# regs register map
Registers from a debugger description file.
Registers are 32-bit, access not given, no defined reset value unless marked. A register's access mark holds for its fields unless they carry their own. Addresses are absolute; registers are grouped by the start of their names; lines under a group give offsets from that group; [hi:lo] are bit positions; {n}, {i} and the like mark numbered series; 'fields as' and 'values as' point back to an identical list; <NAME> marks a mode.

## SC1
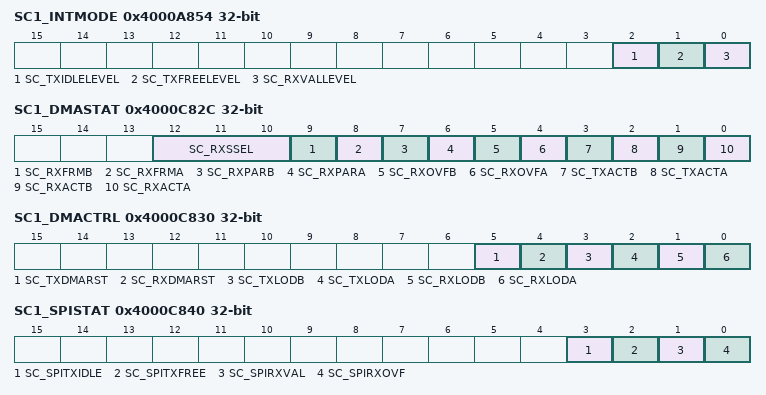
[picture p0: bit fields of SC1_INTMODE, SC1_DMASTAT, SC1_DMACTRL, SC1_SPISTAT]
0x4000A854 SC1_INTMODE
  [2] SC_TXIDLELEVEL, [1] SC_TXFREELEVEL, [0] SC_RXVALLEVEL
0x4000C800 SC1_RXBEGA
0x4000C804 SC1_RXENDA
0x4000C808 SC1_RXBEGB
0x4000C80C SC1_RXENDB
0x4000C810 SC1_TXBEGA
0x4000C814 SC1_TXENDA
0x4000C818 SC1_TXBEGB
0x4000C81C SC1_TXENDB
0x4000C820 SC1_RXCNTA
0x4000C824 SC1_RXCNTB
0x4000C828 SC1_TXCNT
0x4000C82C SC1_DMASTAT
  [12:10] SC_RXSSEL, [9] SC_RXFRMB, [8] SC_RXFRMA, [7] SC_RXPARB, [6] SC_RXPARA, [5] SC_RXOVFB, [4] SC_RXOVFA, [3] SC_TXACTB, [2] SC_TXACTA, [1] SC_RXACTB, [0] SC_RXACTA
0x4000C830 SC1_DMACTRL
  [5] SC_TXDMARST, [4] SC_RXDMARST, [3] SC_TXLODB, [2] SC_TXLODA, [1] SC_RXLODB, [0] SC_RXLODA
0x4000C834 SC1_RXERRA
0x4000C838 SC1_RXERRB
0x4000C83C SC1_DATA
0x4000C840 SC1_SPISTAT
  [3] SC_SPITXIDLE, [2] SC_SPITXFREE, [1] SC_SPIRXVAL, [0] SC_SPIRXOVF
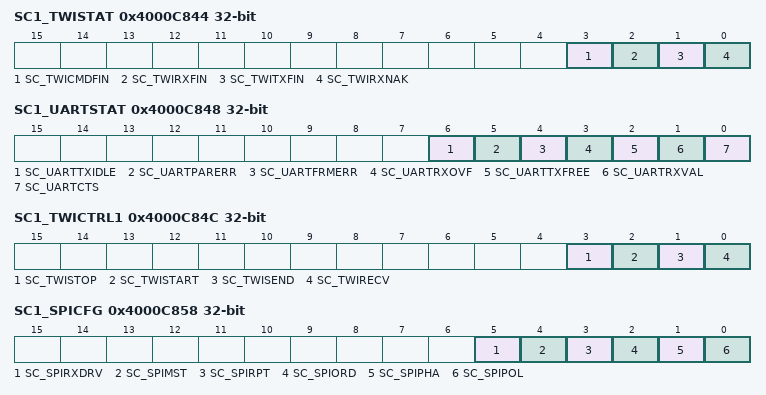
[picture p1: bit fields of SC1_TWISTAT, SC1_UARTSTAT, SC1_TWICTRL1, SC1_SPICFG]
0x4000C844 SC1_TWISTAT
  [3] SC_TWICMDFIN, [2] SC_TWIRXFIN, [1] SC_TWITXFIN, [0] SC_TWIRXNAK
0x4000C848 SC1_UARTSTAT
  [6] SC_UARTTXIDLE, [5] SC_UARTPARERR, [4] SC_UARTFRMERR, [3] SC_UARTRXOVF, [2] SC_UARTTXFREE, [1] SC_UARTRXVAL, [0] SC_UARTCTS
0x4000C84C SC1_TWICTRL1
  [3] SC_TWISTOP, [2] SC_TWISTART, [1] SC_TWISEND, [0] SC_TWIRECV
0x4000C850 SC1_TWICTRL2
0x4000C854 SC1_MODE
0x4000C858 SC1_SPICFG
  [5] SC_SPIRXDRV, [4] SC_SPIMST, [3] SC_SPIRPT, [2] SC_SPIORD, [1] SC_SPIPHA, [0] SC_SPIPOL
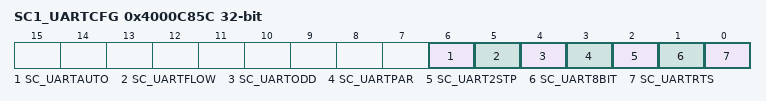
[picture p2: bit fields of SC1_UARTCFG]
0x4000C85C SC1_UARTCFG
  [6] SC_UARTAUTO, [5] SC_UARTFLOW, [4] SC_UARTODD, [3] SC_UARTPAR, [2] SC_UART2STP, [1] SC_UART8BIT, [0] SC_UARTRTS
0x4000C860 SC1_RATELIN
0x4000C864 SC1_RATEEXP
0x4000C868 SC1_UARTPER
0x4000C86C SC1_UARTFRAC
0x4000C870 SC1_RXCNTSAVED

## SC2
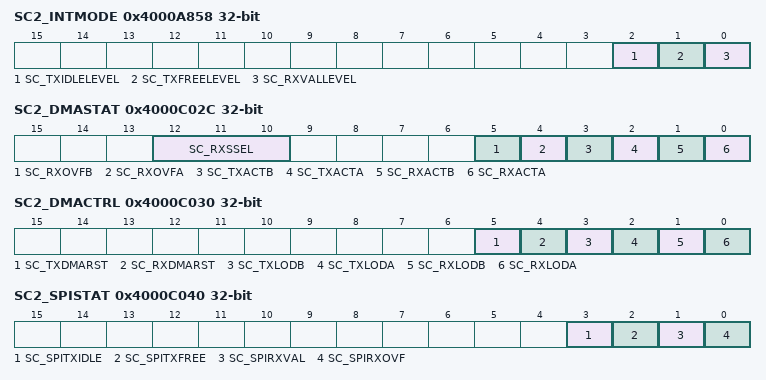
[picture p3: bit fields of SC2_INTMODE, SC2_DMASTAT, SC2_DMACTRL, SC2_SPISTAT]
0x4000A858 SC2_INTMODE
  [2] SC_TXIDLELEVEL, [1] SC_TXFREELEVEL, [0] SC_RXVALLEVEL
0x4000C000 SC2_RXBEGA
0x4000C004 SC2_RXENDA
0x4000C008 SC2_RXBEGB
0x4000C00C SC2_RXENDB
0x4000C010 SC2_TXBEGA
0x4000C014 SC2_TXENDA
0x4000C018 SC2_TXBEGB
0x4000C01C SC2_TXENDB
0x4000C020 SC2_RXCNTA
0x4000C024 SC2_RXCNTB
0x4000C028 SC2_TXCNT
0x4000C02C SC2_DMASTAT
  [12:10] SC_RXSSEL, [5] SC_RXOVFB, [4] SC_RXOVFA, [3] SC_TXACTB, [2] SC_TXACTA, [1] SC_RXACTB, [0] SC_RXACTA
0x4000C030 SC2_DMACTRL
  [5] SC_TXDMARST, [4] SC_RXDMARST, [3] SC_TXLODB, [2] SC_TXLODA, [1] SC_RXLODB, [0] SC_RXLODA
0x4000C034 SC2_RXERRA
0x4000C038 SC2_RXERRB
0x4000C03C SC2_DATA
0x4000C040 SC2_SPISTAT
  [3] SC_SPITXIDLE, [2] SC_SPITXFREE, [1] SC_SPIRXVAL, [0] SC_SPIRXOVF
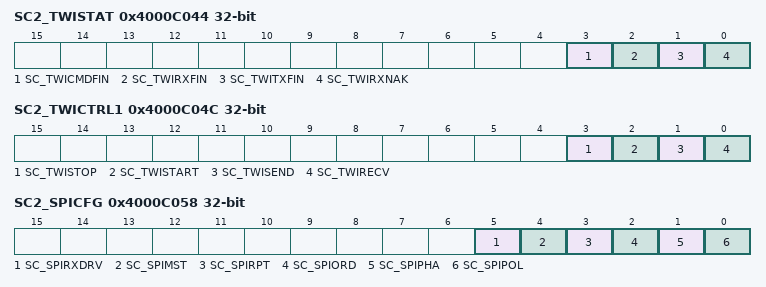
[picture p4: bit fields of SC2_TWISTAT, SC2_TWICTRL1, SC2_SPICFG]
0x4000C044 SC2_TWISTAT
  [3] SC_TWICMDFIN, [2] SC_TWIRXFIN, [1] SC_TWITXFIN, [0] SC_TWIRXNAK
0x4000C04C SC2_TWICTRL1
  [3] SC_TWISTOP, [2] SC_TWISTART, [1] SC_TWISEND, [0] SC_TWIRECV
0x4000C050 SC2_TWICTRL2
0x4000C054 SC2_MODE
0x4000C058 SC2_SPICFG
  [5] SC_SPIRXDRV, [4] SC_SPIMST, [3] SC_SPIRPT, [2] SC_SPIORD, [1] SC_SPIPHA, [0] SC_SPIPOL
0x4000C060 SC2_RATELIN
0x4000C064 SC2_RATEEXP
0x4000C070 SC2_RXCNTSAVED

## GPIO
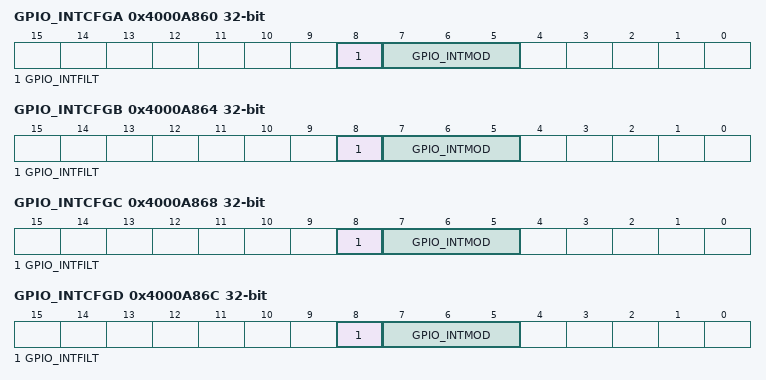
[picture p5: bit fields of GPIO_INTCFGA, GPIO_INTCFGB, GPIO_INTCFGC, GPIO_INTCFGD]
0x4000A860 GPIO_INTCFGA
  [8] GPIO_INTFILT, [7:5] GPIO_INTMOD
0x4000A864 GPIO_INTCFGB
  [8] GPIO_INTFILT, [7:5] GPIO_INTMOD
0x4000A868 GPIO_INTCFGC
  [8] GPIO_INTFILT, [7:5] GPIO_INTMOD
0x4000A86C GPIO_INTCFGD
  [8] GPIO_INTFILT, [7:5] GPIO_INTMOD
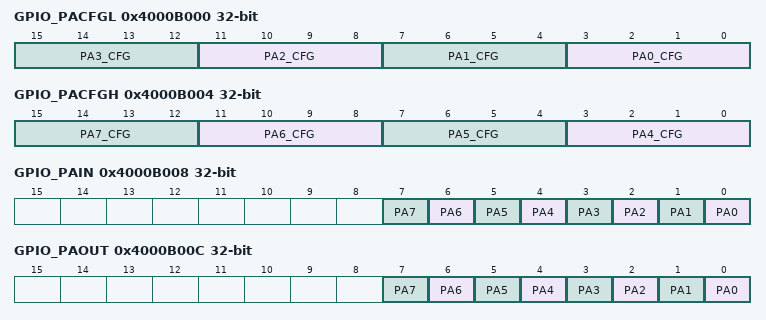
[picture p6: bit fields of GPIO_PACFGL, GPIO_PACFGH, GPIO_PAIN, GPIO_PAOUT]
0x4000B000 GPIO_PACFGL
  [4n+3:4n] PA{n}_CFG (n=0..3)
0x4000B004 GPIO_PACFGH
  [4n-13:4n-16] PA{n}_CFG (n=4..7)
0x4000B008 GPIO_PAIN
  [n] PA{n} (n=0..7)
0x4000B00C GPIO_PAOUT
  [n] PA{n} (n=0..7)
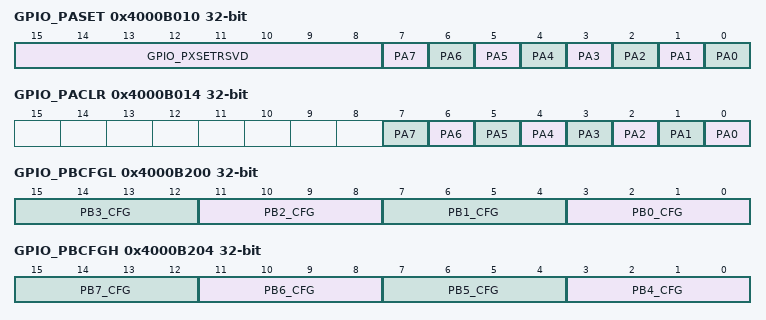
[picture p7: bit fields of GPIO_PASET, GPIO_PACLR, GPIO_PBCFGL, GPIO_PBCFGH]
0x4000B010 GPIO_PASET
  [15:8] GPIO_PXSETRSVD, [n] PA{n} (n=0..7)
0x4000B014 GPIO_PACLR
  [n] PA{n} (n=0..7)
0x4000B200 GPIO_PBCFGL
  [4n+3:4n] PB{n}_CFG (n=0..3)
0x4000B204 GPIO_PBCFGH
  [4n-13:4n-16] PB{n}_CFG (n=4..7)
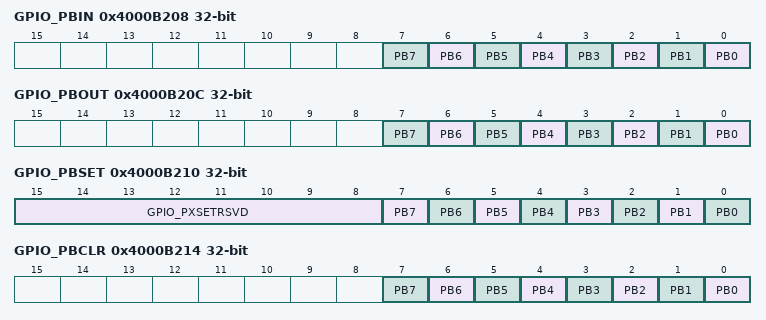
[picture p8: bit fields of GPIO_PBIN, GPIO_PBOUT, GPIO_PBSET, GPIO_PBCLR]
0x4000B208 GPIO_PBIN
  [n] PB{n} (n=0..7)
0x4000B20C GPIO_PBOUT
  [n] PB{n} (n=0..7)
0x4000B210 GPIO_PBSET
  [15:8] GPIO_PXSETRSVD, [n] PB{n} (n=0..7)
0x4000B214 GPIO_PBCLR
  [n] PB{n} (n=0..7)
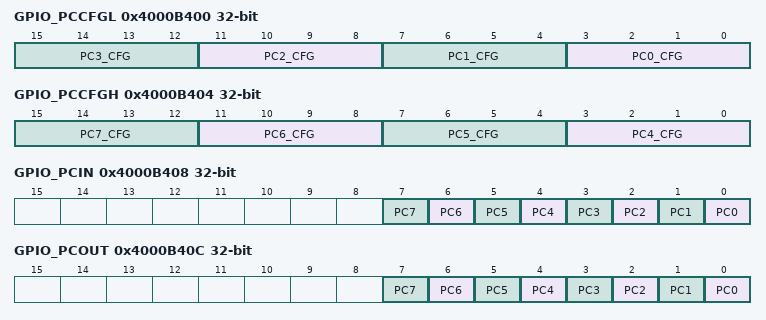
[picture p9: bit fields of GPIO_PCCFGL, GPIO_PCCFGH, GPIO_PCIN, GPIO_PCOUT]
0x4000B400 GPIO_PCCFGL
  [4n+3:4n] PC{n}_CFG (n=0..3)
0x4000B404 GPIO_PCCFGH
  [4n-13:4n-16] PC{n}_CFG (n=4..7)
0x4000B408 GPIO_PCIN
  [n] PC{n} (n=0..7)
0x4000B40C GPIO_PCOUT
  [n] PC{n} (n=0..7)
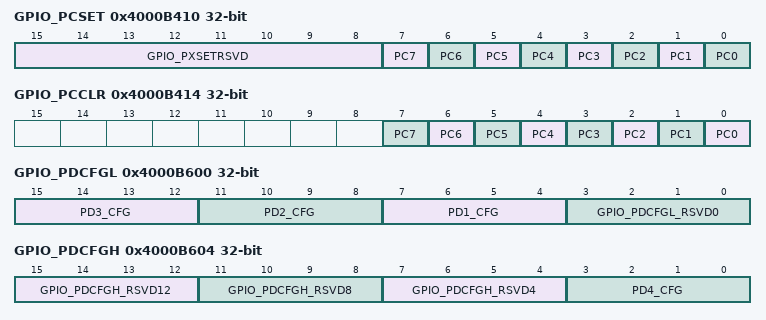
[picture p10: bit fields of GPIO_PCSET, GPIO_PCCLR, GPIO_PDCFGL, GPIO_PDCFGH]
0x4000B410 GPIO_PCSET
  [15:8] GPIO_PXSETRSVD, [n] PC{n} (n=0..7)
0x4000B414 GPIO_PCCLR
  [n] PC{n} (n=0..7)
0x4000B600 GPIO_PDCFGL
  [15:12] PD3_CFG, [11:8] PD2_CFG, [7:4] PD1_CFG, [3:0] GPIO_PDCFGL_RSVD0
0x4000B604 GPIO_PDCFGH
  [15:12] GPIO_PDCFGH_RSVD12, [11:8] GPIO_PDCFGH_RSVD8, [7:4] GPIO_PDCFGH_RSVD4, [3:0] PD4_CFG
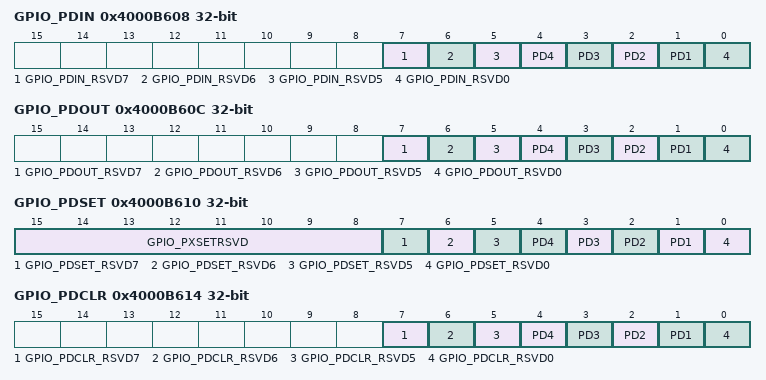
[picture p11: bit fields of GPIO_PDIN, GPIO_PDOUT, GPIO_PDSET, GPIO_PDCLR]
0x4000B608 GPIO_PDIN
  [7] GPIO_PDIN_RSVD7, [6] GPIO_PDIN_RSVD6, [5] GPIO_PDIN_RSVD5, [n] PD{n} (n=1..4), [0] GPIO_PDIN_RSVD0
0x4000B60C GPIO_PDOUT
  [7] GPIO_PDOUT_RSVD7, [6] GPIO_PDOUT_RSVD6, [5] GPIO_PDOUT_RSVD5, [n] PD{n} (n=1..4), [0] GPIO_PDOUT_RSVD0
0x4000B610 GPIO_PDSET
  [15:8] GPIO_PXSETRSVD, [7] GPIO_PDSET_RSVD7, [6] GPIO_PDSET_RSVD6, [5] GPIO_PDSET_RSVD5, [n] PD{n} (n=1..4), [0] GPIO_PDSET_RSVD0
0x4000B614 GPIO_PDCLR
  [7] GPIO_PDCLR_RSVD7, [6] GPIO_PDCLR_RSVD6, [5] GPIO_PDCLR_RSVD5, [n] PD{n} (n=1..4), [0] GPIO_PDCLR_RSVD0
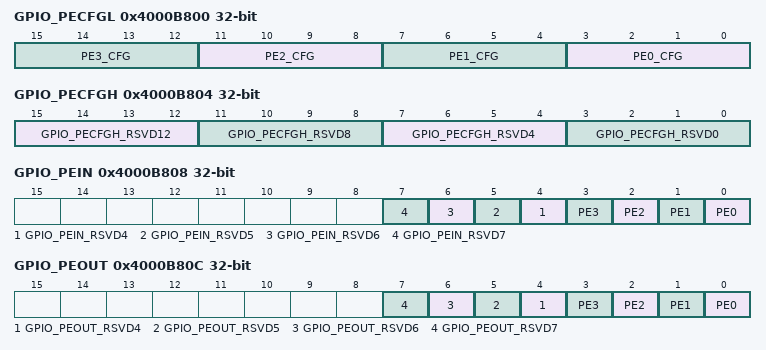
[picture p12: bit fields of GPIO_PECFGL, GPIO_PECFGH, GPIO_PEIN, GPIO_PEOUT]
0x4000B800 GPIO_PECFGL
  [4n+3:4n] PE{n}_CFG (n=0..3)
0x4000B804 GPIO_PECFGH
  [15:12] GPIO_PECFGH_RSVD12, [11:8] GPIO_PECFGH_RSVD8, [7:4] GPIO_PECFGH_RSVD4, [3:0] GPIO_PECFGH_RSVD0
0x4000B808 GPIO_PEIN
  [n] GPIO_PEIN_RSVD{n} (n=4..7), [n] PE{n} (n=0..3)
0x4000B80C GPIO_PEOUT
  [n] GPIO_PEOUT_RSVD{n} (n=4..7), [n] PE{n} (n=0..3)
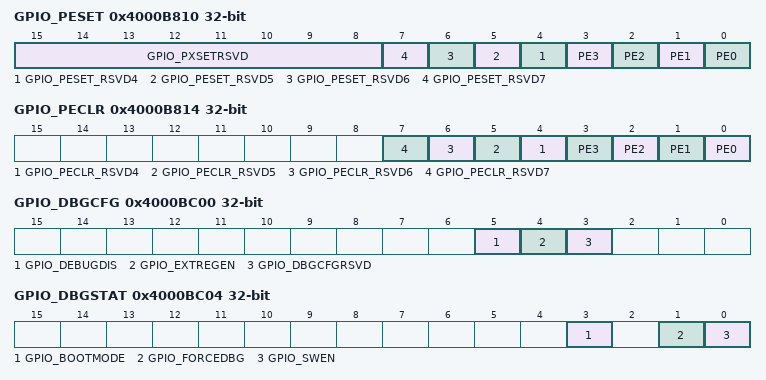
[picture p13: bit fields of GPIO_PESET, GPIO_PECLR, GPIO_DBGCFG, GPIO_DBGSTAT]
0x4000B810 GPIO_PESET
  [15:8] GPIO_PXSETRSVD, [n] GPIO_PESET_RSVD{n} (n=4..7), [n] PE{n} (n=0..3)
0x4000B814 GPIO_PECLR
  [n] GPIO_PECLR_RSVD{n} (n=4..7), [n] PE{n} (n=0..3)
0x4000BC00 GPIO_DBGCFG
  [5] GPIO_DEBUGDIS, [4] GPIO_EXTREGEN, [3] GPIO_DBGCFGRSVD
0x4000BC04 GPIO_DBGSTAT
  [3] GPIO_BOOTMODE, [1] GPIO_FORCEDBG, [0] GPIO_SWEN
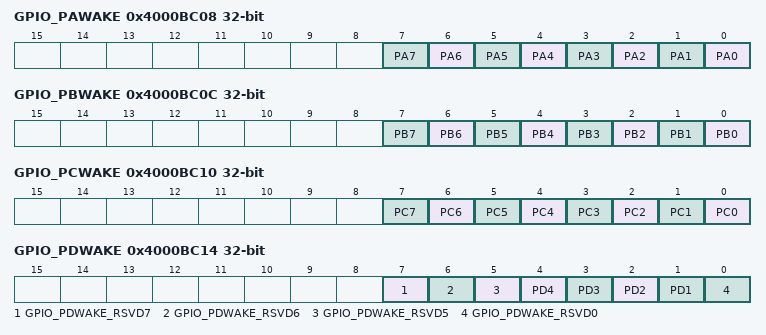
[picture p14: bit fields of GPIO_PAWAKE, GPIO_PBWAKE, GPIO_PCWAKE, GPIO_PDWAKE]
0x4000BC08 GPIO_PAWAKE
  [n] PA{n} (n=0..7)
0x4000BC0C GPIO_PBWAKE
  [n] PB{n} (n=0..7)
0x4000BC10 GPIO_PCWAKE
  [n] PC{n} (n=0..7)
0x4000BC14 GPIO_PDWAKE
  [7] GPIO_PDWAKE_RSVD7, [6] GPIO_PDWAKE_RSVD6, [5] GPIO_PDWAKE_RSVD5, [n] PD{n} (n=1..4), [0] GPIO_PDWAKE_RSVD0
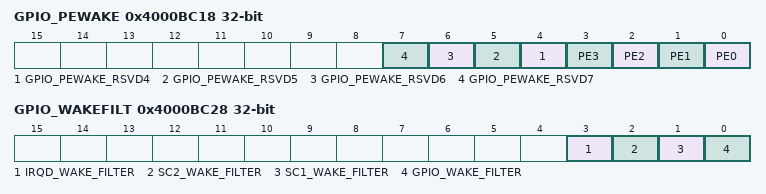
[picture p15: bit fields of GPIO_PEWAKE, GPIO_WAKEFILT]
0x4000BC18 GPIO_PEWAKE
  [n] GPIO_PEWAKE_RSVD{n} (n=4..7), [n] PE{n} (n=0..3)
0x4000BC20 GPIO_IRQCSEL
0x4000BC24 GPIO_IRQDSEL
0x4000BC28 GPIO_WAKEFILT
  [3] IRQD_WAKE_FILTER, [2] SC2_WAKE_FILTER, [1] SC1_WAKE_FILTER, [0] GPIO_WAKE_FILTER

## Notices in the file
Copyright 2015 Silicon Laboratories, Inc.
